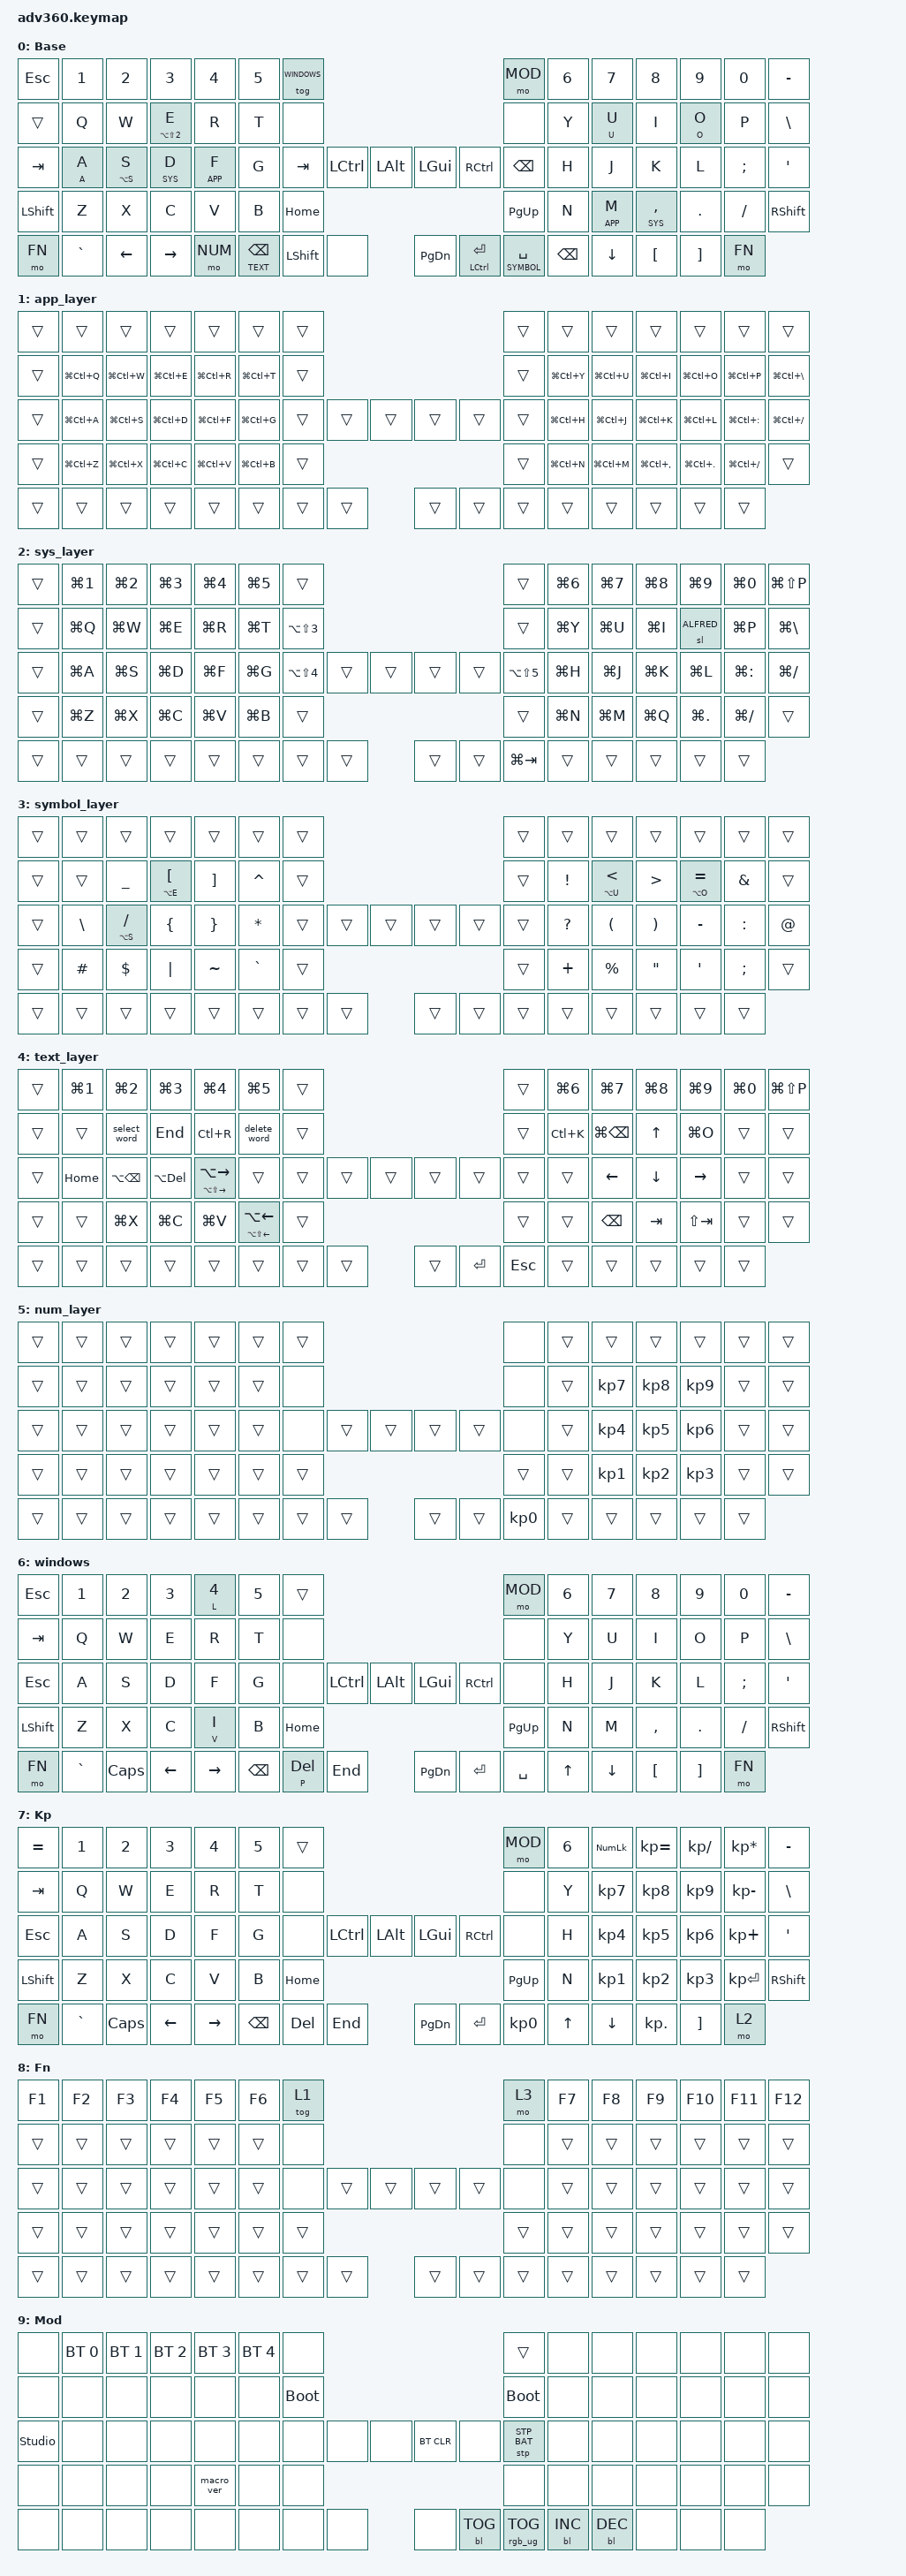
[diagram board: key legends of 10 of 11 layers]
#include <behaviors.dtsi>
#include <dt-bindings/zmk/keys.h>
#include <dt-bindings/zmk/bt.h>
#include <dt-bindings/zmk/rgb.h>
#include <dt-bindings/zmk/stp.h>
#include <dt-bindings/zmk/backlight.h>
#include <dt-bindings/zmk/pointing.h>

#define ___ &trans

#define HM_TAPPING_TERM 300
#define HM_TAPPING_TERM_FAST 200
#define HM_PRIOR_IDLE 150

#define UMLAUT_TAPPING_TERM 350
#define UMLAUT_QUICK_TAP 175

#define MACOS 0
#define APP 1
#define SYS 2
#define SYMBOL 3
#define TEXT 4
#define NUM 5
#define WINDOWS 6
#define KEYPAD 7
#define FN 8
#define MOD 9
#define ALFRED 10

#define KEYS_LEFT 0 1 2 3 4 5 6 \
                  14 15 16 17 18 19 20 \
                  28 29 30 31 32 33 34 \
                  46 47 48 49 50 51 \
                  66 67 68 69 70

#define KEYS_LEFT_L 32

#define KEYS_RIGHT 7 8 9 10 11 12 13 \
                   21 22 23 24 25 26 27 \
                   39 40 41 42 43 44 45 \
                   60 61 62 63 64 65 \
                   77 78 79 80 81

#define THUMBS_LEFT 35 36 54 71 72 73

#define THUMBS_RIGHT 37 38 57 74 75 76

#define THUMBS THUMBS_LEFT THUMBS_RIGHT

/ {
    macros {
        umlaut_x: umlaut_x {
            compatible = "zmk,behavior-macro-one-param";
            #binding-cells = <1>;
            bindings =
                <&kp LA(U)>,
                <&macro_param_1to1>,
                <&kp MACRO_PLACEHOLDER>;
        };

        delete_word: delete_word {
            compatible = "zmk,behavior-macro";
            #binding-cells = <0>;
            bindings = 
                <&kp LA(BSPC)>,
                <&kp LA(DEL)>;
        };

        select_word: select_word {
            compatible = "zmk,behavior-macro";
            #binding-cells = <0>;
            bindings = 
                <&kp LA(LEFT)>,
                <&kp LA(LS(RIGHT))>;
        };
    };

    behaviors {
      #include "macros.dtsi"
      #include "version.dtsi"

      hm_l: homerow_mods_left {
          compatible = "zmk,behavior-hold-tap";
          label = "HOMEROW_MODS_LEFT";
          #binding-cells = <2>;
          tapping-term-ms = <HM_TAPPING_TERM>;
          quick-tap-ms = <175>;
          require-prior-idle-ms = <HM_PRIOR_IDLE>;
          flavor = "balanced";
          bindings = <&mo>, <&kp>;
          hold-trigger-key-positions = <KEYS_RIGHT THUMBS>;
          hold-trigger-on-release;
      };

      hm_r: homerow_mods_right {
          compatible = "zmk,behavior-hold-tap";
          label = "HOMEROW_MODS_RIGHT";
          #binding-cells = <2>;
          tapping-term-ms = <HM_TAPPING_TERM>;
          quick-tap-ms = <175>;
          require-prior-idle-ms = <HM_PRIOR_IDLE>;
          flavor = "balanced";
          bindings = <&mo>, <&kp>;
          hold-trigger-key-positions = <KEYS_LEFT THUMBS>;
          hold-trigger-on-release;
      };

      // Positional Homerow mods for shift
      // Use faster tapping term and disable some features that may
      // cause false negatives.
      hm_ls: hm_shift_l {
          compatible = "zmk,behavior-hold-tap";
          #binding-cells = <2>;
          bindings = <&kp>, <&kp>;

          flavor = "balanced";
          tapping-term-ms = <HM_TAPPING_TERM_FAST>;
          quick-tap-ms = <175>;
          require-prior-idle-ms = <HM_PRIOR_IDLE>;

          hold-trigger-key-positions = <KEYS_RIGHT THUMBS>;
          // hold-trigger-on-release;
      };

      hm_rs: hm_shift_r {
          compatible = "zmk,behavior-hold-tap";
          #binding-cells = <2>;
          bindings = <&kp>, <&kp>;

          flavor = "balanced";
          tapping-term-ms = <HM_TAPPING_TERM_FAST>;
          quick-tap-ms = <175>;
          require-prior-idle-ms = <HM_PRIOR_IDLE>;

          hold-trigger-key-positions = <KEYS_LEFT THUMBS>;
          // hold-trigger-on-release;
      };

      umlaut_ae: umlaut_ae {
          compatible = "zmk,behavior-mod-morph";
          #binding-cells = <0>;
          bindings = <&umlaut_x A>, <&umlaut_x LS(A)>;
          mods = <(MOD_LSFT|MOD_RSFT)>;
          keep-mods = <0>;
      };

      umlaut_tap_ae: umlaut_tap_ae {
          compatible = "zmk,behavior-hold-tap";
          #binding-cells = <2>;
          tapping-term-ms = <UMLAUT_TAPPING_TERM>;
          quick-tap-ms = <UMLAUT_QUICK_TAP>;
          flavor = "tap-preferred";
          bindings = <&umlaut_ae>, <&kp>;
      };

      umlaut_ue: umlaut_ue {
          compatible = "zmk,behavior-mod-morph";
          #binding-cells = <0>;
          bindings = <&umlaut_x U>, <&umlaut_x LS(U)>;
          mods = <(MOD_LSFT|MOD_RSFT)>;
          keep-mods = <0>;
      };

      umlaut_tap_ue: umlaut_tap_ue {
          compatible = "zmk,behavior-hold-tap";
          #binding-cells = <2>;
          tapping-term-ms = <UMLAUT_TAPPING_TERM>;
          quick-tap-ms = <UMLAUT_QUICK_TAP>;
          flavor = "tap-preferred";
          bindings = <&umlaut_ue>, <&kp>;
      };

      umlaut_oe: umlaut_oe {
          compatible = "zmk,behavior-mod-morph";
          #binding-cells = <0>;
          bindings = <&umlaut_x O>, <&umlaut_x LS(O)>;
          mods = <(MOD_LSFT|MOD_RSFT)>;
          keep-mods = <0>;
      };

      umlaut_tap_oe: umlaut_tap_oe {
          compatible = "zmk,behavior-hold-tap";
          #binding-cells = <2>;
          tapping-term-ms = <UMLAUT_TAPPING_TERM>;
          quick-tap-ms = <UMLAUT_QUICK_TAP>;
          flavor = "tap-preferred";
          bindings = <&umlaut_oe>, <&kp>;
      };

      // Custom mod-tap with your timing
      cmt: custom_mod_tap {
          compatible = "zmk,behavior-hold-tap";
          #binding-cells = <2>;
          tapping-term-ms = <UMLAUT_TAPPING_TERM>;
          quick-tap-ms = <UMLAUT_QUICK_TAP>;
          flavor = "tap-preferred";
          bindings = <&kp>, <&kp>;
      };
    };

  keymap {
    compatible = "zmk,keymap";

    default_layer {
      display-name = "Base";
      bindings = <
        &kp ESC   &kp N1              &kp N2          &kp N3             &kp N4             &kp N5  &tog WINDOWS                                                          &mo MOD      &kp N6  &kp N7              &kp N8            &kp N9              &kp N0    &kp MINUS
        ___       &kp Q               &kp W           &cmt LA(LS(N2)) E  &kp R              &kp T   &none                                                                 &none        &kp Y   &umlaut_tap_ue U U  &kp I             &umlaut_tap_oe O O  &kp P     &kp BSLH
        &kp TAB   &umlaut_tap_ae A A  &cmt LA(S) S    &hm_l SYS D        &hm_l APP F        &kp G   &kp TAB         &kp LCTRL &kp LALT &kp LGUI  &kp RCTRL                &kp BSPC     &kp H   &kp J               &kp K             &kp L               &kp SEMI        &kp SQT
        &kp LSHFT &kp Z               &kp X           &kp C              &kp V              &kp B                             &kp HOME &kp PG_UP                                       &kp N   &hm_r APP M         &hm_r SYS COMMA   &kp DOT             &kp FSLH  &kp RSHFT
        &mo FN    &kp GRAVE           &kp LEFT        &kp RIGHT          &mo NUM                &lt TEXT BSPC  &kp LSHIFT &none    &kp PG_DN &mt LCTRL ENTER &lt SYMBOL SPACE &kp BSPC        &kp DOWN         &kp LBKT      &kp RBKT  &mo FN
      >;
    };

    app_layer {
      bindings = <
        ___            ___        ___        ___        ___           ___            ___                                    ___             ___             ___            ___           ___          ___           ___
        ___            &kp LG(LC(Q))  &kp LG(LC(W))  &kp LG(LC(E))  &kp LG(LC(R))     &kp LG(LC(T))      ___                                    ___             &kp LG(LC(Y))       &kp LG(LC(U))      &kp LG(LC(I))     &kp LG(LC(O))    &kp LG(LC(P))     &kp LG(LC(BSLH))
        ___            &kp LG(LC(A))  &kp LG(LC(S))  &kp LG(LC(D))  &kp LG(LC(F))     &kp LG(LC(G))      ___         ___ ___ ___ ___            ___             &kp LG(LC(H))       &kp LG(LC(J))      &kp LG(LC(K))     &kp LG(LC(L))    &kp LG(LC(COLON)) &kp LG(LC(FSLH))
        ___            &kp LG(LC(Z))  &kp LG(LC(X))  &kp LG(LC(C))  &kp LG(LC(V))     &kp LG(LC(B))                      ___ ___                                &kp LG(LC(N))       &kp LG(LC(M))      &kp LG(LC(COMMA)) &kp LG(LC(DOT))  &kp LG(LC(SLASH)) ___
        ___            ___        ___        ___        ___                                 ___ ___  ___ ___  ___ ___                                       ___            ___           ___          ___           ___
      >;
    };

    sys_layer {
      bindings = <
        ___            &kp LG(N1) &kp LG(N2) &kp LG(N3) &kp LG(N4)    &kp LG(N5)     ___                                           ___             &kp LG(N6)     &kp LG(N7)     &kp LG(N8)    &kp LG(N9)   &kp LG(N0)    &kp LG(LS(P))
        ___            &kp LG(Q)  &kp LG(W)  &kp LG(E)  &kp LG(R)     &kp LG(T)      &kp LA(LS(N3))                                ___             &kp LG(Y)      &kp LG(U)      &kp LG(I)     &sl ALFRED   &kp LG(P)     &kp LG(BSLH)
        ___            &kp LG(A)  &kp LG(S)  &kp LG(D)  &kp LG(F)     &kp LG(G)      &kp LA(LS(N4))         ___ ___ ___ ___        &kp LA(LS(N5))  &kp LG(H)      &kp LG(J)      &kp LG(K)     &kp LG(L)    &kp LG(COLON) &kp LG(FSLH)
        ___            &kp LG(Z)  &kp LG(X)  &kp LG(C)  &kp LG(V)     &kp LG(B)                                 ___ ___                            &kp LG(N)      &kp LG(M)      &kp LG(Q)     &kp LG(DOT)  &kp LG(SLASH) ___
        ___            ___        ___        ___        ___                                            ___ ___  ___ ___  ___ &kp LG(TAB)                          ___            ___           ___          ___           ___
      >;
    };

    symbol_layer {
      bindings = <
        ___            ___            ___             ___             ___       ___            ___                                    ___             ___            ___            ___           ___              ___           ___
        ___            ___            &kp UNDER       &mt LA(E) LBKT  &kp RBKT  &kp CARET      ___                                    ___             &kp EXCL       &mt LA(U) LT   &kp GT        &mt LA(O) EQUAL  &kp AMPS      ___ 
        ___            &kp BSLH       &mt LA(S) FSLH  &kp LBRC        &kp RBRC  &kp STAR       ___         ___ ___ ___ ___            ___             &kp QMARK      &kp LPAR       &kp RPAR      &kp MINUS        &kp COLON     &kp AT 
        ___            &kp HASH       &kp DOLLAR      &kp PIPE        &kp TILDE &kp GRAVE                      ___ ___                                &kp PLUS       &kp PERCENT    &kp DQT       &kp SQT          &kp SEMI      ___
        ___            ___            ___             ___             ___                             ___ ___  ___ ___  ___ ___                                      ___            ___           ___              ___           ___
      >;
    };

    text_layer {
      bindings = <
        ___            &kp LG(N1)     &kp LG(N2)      &kp LG(N3)      &kp LG(N4)                   &kp LG(N5)                 ___                                    ___             &kp LG(N6)     &kp LG(N7)     &kp LG(N8)    &kp LG(N9)       &kp LG(N0)   &kp LG(LS(P))
        ___            ___            &select_word    &kp END         &kp LC(R)                    &delete_word               ___                                    ___             &kp LC(K)      &kp LG(BSPC)   &kp UP        &kp LG(O)        ___      ___ 
        ___            &kp HOME       &kp LA(BSPC)    &kp LA(DELETE)  &mt LA(LS(RIGHT)) LA(RIGHT)  ___                        ___                  ___ ___ ___ ___   ___             ___            &kp LEFT       &kp DOWN      &kp RIGHT        ___      ___
        ___            ___            &kp LG(X)       &kp LG(C)       &kp LG(V)                    &mt LA(LS(LEFT)) LA(LEFT)                           ___ ___                                ___            &kp BSPC       &kp TAB       &kp LS(TAB)      ___      ___
        ___            ___            ___             ___             ___                                                                     ___ ___  ___ ___  &kp ENTER &kp ESC             ___            ___           ___              ___      ___
      >;
    };

    num_layer {
      bindings = <
        &trans &trans &trans &trans &trans &trans  &trans                                          &none &trans    &trans    &trans    &trans     &trans  &trans
        &trans &trans &trans &trans &trans &trans  &none                                           &none &trans    &kp KP_N7 &kp KP_N8 &kp KP_N9  &trans  &trans
        &trans &trans &trans &trans &trans &trans  &none        &trans &trans &trans &trans        &none &trans    &kp KP_N4 &kp KP_N5 &kp KP_N6  &trans  &trans
        &trans &trans &trans &trans &trans &trans                      &trans &trans                     &trans    &kp KP_N1 &kp KP_N2 &kp KP_N3  &trans  &trans
        &trans &trans &trans &trans &trans               &trans &trans &trans &trans &trans &kp KP_N0              &trans    &trans    &trans     &trans  &trans
      >;
    };

    windows {
      bindings = <
        &kp ESC   &kp N1    &kp N2   &kp N3   &mt L N4    &kp N5 &trans                                                              &mo MOD &kp N6 &kp N7 &kp N8    &kp N9   &kp N0   &kp MINUS
        &kp TAB   &kp Q     &kp W    &kp E    &kp R       &kp T  &none                                                               &none   &kp Y  &kp U  &kp I     &kp O    &kp P    &kp BSLH
        &kp ESC   &kp A     &kp S    &kp D    &kp F       &kp G  &none           &kp LCTRL &kp LALT &kp LGUI  &kp RCTRL              &none   &kp H  &kp J  &kp K     &kp L    &kp SEMI &kp SQT
        &kp LSHFT &kp Z     &kp X    &kp C    &mt V I     &kp B                            &kp HOME &kp PG_UP                                &kp N  &kp M  &kp COMMA &kp DOT  &kp FSLH &kp RSHFT
        &mo FN    &kp GRAVE &kp CAPS &kp LEFT &kp RIGHT                 &kp BSPC &mt P DEL &kp END  &kp PG_DN &kp ENTER &kp SPACE                   &kp UP &kp DOWN  &kp LBKT &kp RBKT &mo FN
      >;
    };

    keypad {
      display-name = "Kp";
      bindings = <
        &kp EQUAL &kp N1    &kp N2   &kp N3   &kp N4     &kp N5 &trans                                                           &mo MOD &kp N6 &kp KP_NUM &kp KP_EQUAL &kp KP_DIVIDE &kp KP_MULTIPLY &kp MINUS
        &kp TAB   &kp Q     &kp W    &kp E    &kp R      &kp T  &none                                                            &none   &kp Y  &kp KP_N7  &kp KP_N8    &kp KP_N9     &kp KP_MINUS    &kp BSLH
        &kp ESC   &kp A     &kp S    &kp D    &kp F      &kp G  &none           &kp LCTRL &kp LALT &kp LGUI  &kp RCTRL           &none   &kp H  &kp KP_N4  &kp KP_N5    &kp KP_N6     &kp KP_PLUS     &kp SQT
        &kp LSHFT &kp Z     &kp X    &kp C    &kp V      &kp B                            &kp HOME &kp PG_UP                             &kp N  &kp KP_N1  &kp KP_N2    &kp KP_N3     &kp KP_ENTER    &kp RSHFT
        &mo FN    &kp GRAVE &kp CAPS &kp LEFT &kp RIGHT                &kp BSPC &kp DEL   &kp END  &kp PG_DN &kp ENTER &kp KP_N0                &kp UP     &kp DOWN     &kp KP_DOT    &kp RBKT        &mo 2
      >;
    };

    fn {
      display-name = "Fn";
      bindings = <
        &kp F1 &kp F2 &kp F3 &kp F4 &kp F5 &kp F6 &tog 1                                           &mo 3 &kp F7 &kp F8 &kp F9 &kp F10 &kp F11 &kp F12
        &trans &trans &trans &trans &trans &trans  &none                                           &none &trans &trans &trans &trans  &trans  &trans
        &trans &trans &trans &trans &trans &trans  &none        &trans &trans &trans &trans        &none &trans &trans &trans &trans  &trans  &trans
        &trans &trans &trans &trans &trans &trans                      &trans &trans                     &trans &trans &trans &trans  &trans  &trans
        &trans &trans &trans &trans &trans               &trans &trans &trans &trans &trans &trans              &trans &trans &trans  &trans  &trans
      >;
    };

    mod {
      display-name = "Mod";
      bindings = <
        &none &bt BT_SEL 0 &bt BT_SEL 1 &bt BT_SEL 2 &bt BT_SEL 3 &bt BT_SEL 4 &none                                                                     &trans                 &none        &none        &none        &none &none &none
        &none &none        &none        &none        &none        &none        &bootloader                                                               &bootloader            &none        &none        &none        &none &none &none
        &studio_unlock &none        &none        &none        &none        &none        &none                   &none &none &bt BT_CLR &none                      &stp STP_BAT &none        &none        &none        &none &none &none
        &none &none        &none        &none        &macro_ver   &none                                      &none &none                                                        &none        &none        &none        &none &none &none
        &none &none        &none        &none        &none                                       &none &none &none &none      &bl BL_TOG &rgb_ug RGB_TOG                                     &bl BL_INC   &bl BL_DEC   &none &none &none
      >;
    };

    alfred {
      display-name = "Alfred";
      bindings = <
        &kp F1 &kp F2 &kp F3            &kp F4            &kp F5            &kp F6  &tog 1                                          &mo 3 &kp F7 &kp F8            &kp F9            &kp F10 &kp F11 &kp F12
        &trans &trans &kp LG(LA(LS(W))) &trans            &trans            &trans  &none                                           &none &trans &trans            &trans            &trans  &trans  &trans
        &trans &trans &trans            &kp LG(LA(LS(D))) &trans            &trans  &none        &trans &trans &trans &trans        &none &trans &trans            &trans            &trans  &trans  &trans
        &trans &trans &trans            &kp LG(LA(LS(C))) &kp LG(LA(LS(V))) &trans                      &trans &trans                     &kp LG(LA(LS(N)))        &kp LG(LA(LS(M))) &trans  &trans  &trans  &trans
        &trans &trans &trans            &trans            &trans               &trans &trans &trans &trans &trans &trans                                           &trans            &trans  &trans  &trans  &trans
      >;
    };

    extra1 { 
      display-name = "Red";    
      status = "reserved";
    };

    extra2 { 
      display-name = "Purple";    
      status = "reserved";
    };

    extra3 { 
      display-name = "Cyan";    
      status = "reserved";
    };

    extra4 { 
      display-name = "Yellow";    
      status = "reserved";
    };
  };
};
